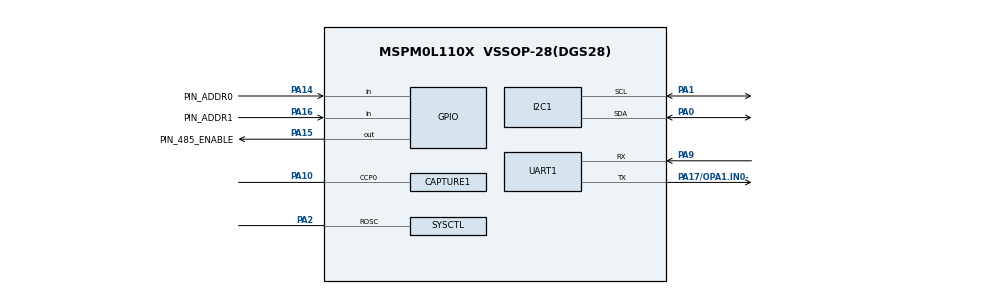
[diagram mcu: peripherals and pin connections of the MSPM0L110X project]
/**
 * @cliArgs --device "MSPM0L110X" --part "Default" --package "VSSOP-28(DGS28)" --product "mspm0_sdk@2.10.00.04"
 * @versions {"tool":"1.27.1+4634"}
 */

/**
 * Import the modules used in this configuration.
 */
const ADC12    = scripting.addModule("/ti/driverlib/ADC12", {}, false);
const ADC121   = ADC12.addInstance();
const Board    = scripting.addModule("/ti/driverlib/Board");
const CAPTURE  = scripting.addModule("/ti/driverlib/CAPTURE", {}, false);
const CAPTURE1 = CAPTURE.addInstance();
const GPIO     = scripting.addModule("/ti/driverlib/GPIO", {}, false);
const GPIO1    = GPIO.addInstance();
const GPIO2    = GPIO.addInstance();
const GPIO3    = GPIO.addInstance();
const I2C      = scripting.addModule("/ti/driverlib/I2C", {}, false);
const I2C1     = I2C.addInstance();
const SYSCTL   = scripting.addModule("/ti/driverlib/SYSCTL");
const TIMER    = scripting.addModule("/ti/driverlib/TIMER", {}, false);
const TIMER1   = TIMER.addInstance();
const TIMER2   = TIMER.addInstance();
const UART     = scripting.addModule("/ti/driverlib/UART", {}, false);
const UART1    = UART.addInstance();
const WWDT     = scripting.addModule("/ti/driverlib/WWDT", {}, false);
const WWDT1    = WWDT.addInstance();

/**
 * Write custom configuration values to the imported modules.
 */
ADC121.$name                             = "ADC0";
ADC121.samplingOperationMode             = "sequence";
ADC121.adcMem1chansel                    = "DL_ADC12_INPUT_CHAN_1";
ADC121.adcMem2chansel                    = "DL_ADC12_INPUT_CHAN_2";
ADC121.adcMem2trig                       = "DL_ADC12_TRIGGER_MODE_TRIGGER_NEXT";
ADC121.endAdd                            = 3;
ADC121.adcMem3chansel                    = "DL_ADC12_INPUT_CHAN_3";
ADC121.enabledInterrupts                 = ["DL_ADC12_INTERRUPT_MEM0_RESULT_LOADED","DL_ADC12_INTERRUPT_MEM1_RESULT_LOADED","DL_ADC12_INTERRUPT_MEM2_RESULT_LOADED","DL_ADC12_INTERRUPT_MEM3_RESULT_LOADED"];
ADC121.subChanID                         = 1;
ADC121.adcMem3trig                       = "DL_ADC12_TRIGGER_MODE_TRIGGER_NEXT";
ADC121.sampleTime0                       = "0.001 ms";
ADC121.adcMem3avgen                      = true;
ADC121.hwNumerator                       = "DL_ADC12_HW_AVG_NUM_ACC_16";
ADC121.hwDenominator                     = "DL_ADC12_HW_AVG_DEN_DIV_BY_4";
ADC121.adcPin0Config.hideOutputInversion = scripting.forceWrite(false);
ADC121.adcPin0Config.$name               = "ti_driverlib_gpio_GPIOPinGeneric4";
ADC121.adcPin0Config.enableConfig        = true;
ADC121.adcPin1Config.$name               = "ti_driverlib_gpio_GPIOPinGeneric5";
ADC121.adcPin1Config.enableConfig        = true;
ADC121.adcPin2Config.$name               = "ti_driverlib_gpio_GPIOPinGeneric6";
ADC121.adcPin2Config.enableConfig        = true;
ADC121.peripheral.$assign                = "ADC0";
ADC121.peripheral.adcPin0.$assign        = "PA27";
ADC121.peripheral.adcPin1.$assign        = "PA26";
ADC121.peripheral.adcPin2.$assign        = "PA25";
ADC121.peripheral.adcPin3.$assign        = "PA24/OPA0.IN0-";
ADC121.adcPin3Config.$name               = "ti_driverlib_gpio_GPIOPinGeneric8";


CAPTURE1.$name                          = "CAPTURE_0";
CAPTURE1.multi_countMode                = "DL_TIMER_COUNT_MODE_UP";
CAPTURE1.multi_countRep                 = "DL_TIMER_REPEAT_MODE_ENABLED";
CAPTURE1.multi_cvae                     = "DL_TIMER_COUNT_AFTER_EN_ZERO";
CAPTURE1.ccIndexMulti                   = [0];
CAPTURE1.captMode                       = "COMBINED";
CAPTURE1.timerClkPrescale               = 8;
CAPTURE1.interrupts                     = ["CC1_DN","ZERO"];
CAPTURE1.peripheral.$assign             = "TIMG4";
CAPTURE1.peripheral.ccp0Pin.$assign     = "PA10";
CAPTURE1.ccp0PinConfig.$name            = "ti_driverlib_gpio_GPIOPinGeneric7";
CAPTURE1.ccp0PinConfig.enableConfig     = true;
CAPTURE1.ccp0PinConfig.internalResistor = "PULL_DOWN";

GPIO1.port                          = "PORTA";
GPIO1.$name                         = "MCU_GPIO";
GPIO1.associatedPins[0].$name       = "MCU_GPIO0_1";
GPIO1.associatedPins[0].direction   = "INPUT";
GPIO1.associatedPins[0].assignedPin = "18";

GPIO2.$name                                 = "GPIO_ADDR_GRP";
GPIO2.port                                  = "PORTA";
GPIO2.associatedPins.create(2);
GPIO2.associatedPins[0].direction           = "INPUT";
GPIO2.associatedPins[0].assignedPortSegment = "Lower";
GPIO2.associatedPins[0].$name               = "PIN_ADDR0";
GPIO2.associatedPins[0].internalResistor    = "PULL_DOWN";
GPIO2.associatedPins[0].pin.$assign         = "PA14";
GPIO2.associatedPins[1].direction           = "INPUT";
GPIO2.associatedPins[1].assignedPortSegment = "Upper";
GPIO2.associatedPins[1].$name               = "PIN_ADDR1";
GPIO2.associatedPins[1].internalResistor    = "PULL_DOWN";
GPIO2.associatedPins[1].pin.$assign         = "PA16";

GPIO3.$name                              = "GPIO_485_GRP";
GPIO3.port                               = "PORTA";
GPIO3.associatedPins[0].internalResistor = "PULL_DOWN";
GPIO3.associatedPins[0].$name            = "PIN_485_ENABLE";
GPIO3.associatedPins[0].pin.$assign      = "PA15";

I2C1.basicEnableTarget                 = true;
I2C1.$name                             = "TAR_I2C";
I2C1.advEnableAfterInit                = false;
I2C1.advTargetTXEmptyEn                = true;
I2C1.basicTargetSecAddressEnable       = true;
I2C1.basicTargetAddress                = 0x48;
I2C1.basicTargetSecAddress             = 0x20;
I2C1.peripheral.$assign                = "I2C0";
I2C1.peripheral.sdaPin.$assign         = "PA0";
I2C1.peripheral.sclPin.$assign         = "PA1";
I2C1.sdaPinConfig.hideOutputInversion  = scripting.forceWrite(false);
I2C1.sdaPinConfig.onlyInternalResistor = scripting.forceWrite(false);
I2C1.sdaPinConfig.passedPeripheralType = scripting.forceWrite("Digital");
I2C1.sdaPinConfig.$name                = "ti_driverlib_gpio_GPIOPinGeneric0";
I2C1.sclPinConfig.hideOutputInversion  = scripting.forceWrite(false);
I2C1.sclPinConfig.onlyInternalResistor = scripting.forceWrite(false);
I2C1.sclPinConfig.passedPeripheralType = scripting.forceWrite("Digital");
I2C1.sclPinConfig.$name                = "ti_driverlib_gpio_GPIOPinGeneric1";

SYSCTL.enableROSC                 = true;
SYSCTL.enableSYSOSCFCL            = true;
SYSCTL.peripheral.$assign         = "SYSCTL";
SYSCTL.peripheral.roscPin.$assign = "PA2";

TIMER1.$name              = "WAKEUP_TIMER";
TIMER1.timerClkSrc        = "LFCLK";
TIMER1.timerMode          = "PERIODIC";
TIMER1.timerPeriod        = "500 ms";
TIMER1.timerStartTimer    = true;
TIMER1.interrupts         = ["ZERO"];
TIMER1.peripheral.$assign = "TIMG0";

TIMER2.timerClkDiv                 = 2;
TIMER2.timerMode                   = "PERIODIC";
TIMER2.event1PublisherChannel      = 1;
TIMER2.event1ControllerInterruptEn = ["ZERO_EVENT"];
TIMER2.$name                       = "TIMER_ACMEAS";
TIMER2.timerPeriod                 = "62.5us";
TIMER2.peripheral.$assign          = "TIMG1";

UART1.$name                    = "UART_0";
UART1.peripheral.rxPin.$assign = "PA9";
UART1.peripheral.txPin.$assign = "PA17/OPA1.IN0-";
UART1.txPinConfig.$name        = "ti_driverlib_gpio_GPIOPinGeneric2";
UART1.rxPinConfig.$name        = "ti_driverlib_gpio_GPIOPinGeneric3";

WWDT1.$name              = "WWDT0";
WWDT1.clockDivider       = "5";
WWDT1.periodCount        = "15";
WWDT1.peripheral.$assign = "WWDT0";

/**
 * Pinmux solution for unlocked pins/peripherals. This ensures that minor changes to the automatic solver in a future
 * version of the tool will not impact the pinmux you originally saw.  These lines can be completely deleted in order to
 * re-solve from scratch.
 */
Board.peripheral.$suggestSolution            = "DEBUGSS";
Board.peripheral.swclkPin.$suggestSolution   = "PA20";
Board.peripheral.swdioPin.$suggestSolution   = "PA19";
GPIO1.associatedPins[0].pin.$suggestSolution = "PA18";
UART1.peripheral.$suggestSolution            = "UART0";
